AUTOSAR XML (schema 4-2-2)
package /Components
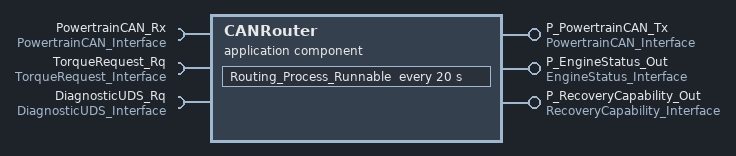
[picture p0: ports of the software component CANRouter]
  application sw component type CANRouter
    provide port P_PowertrainCAN_Tx: provided-interface=PowertrainCAN_Interface
    provide port P_EngineStatus_Out: provided-interface=EngineStatus_Interface
    provide port P_RecoveryCapability_Out: provided-interface=RecoveryCapability_Interface
    require port PowertrainCAN_Rx: required-interface=PowertrainCAN_Interface
    require port TorqueRequest_Rq: required-interface=TorqueRequest_Interface
    require port DiagnosticUDS_Rq: required-interface=DiagnosticUDS_Interface
    behavior CANRouterBehavior
      external trigger occurred event CAN_Frame_Received_Event: start-on-event=Routing_Process_Runnable
      timing event Routing_Periodic_Event: start-on-event=Routing_Process_Runnable, period=20
      runnable Routing_Process_Runnable: minimum-start-interval=20, symbol=CANRouter_Routing_Process_Runnable
        data-receive-point-by-arguments:
          access Recv_Powertrain_CAN: accessed-variable=PowertrainCAN_Rx.CAN_Frame
          access Recv_TorqueRequest: accessed-variable=TorqueRequest_Rq.TorqueRequest
        data-send-points:
          access Send_Powertrain_CAN: accessed-variable=P_PowertrainCAN_Tx.CAN_Frame
          access Send_EngineStatus: accessed-variable=P_EngineStatus_Out.EngineStatus
          access Send_RecoveryCapability: accessed-variable=P_RecoveryCapability_Out.RecoveryCapability
        sync call ConfigSyncCall: operation=DiagnosticUDS_Rq.UpdateMapping, timeout=100
